# DDR32SS0_CTLPHY_WRAP_CTL_CFG_CTLCFG register map
Vendor: Texas Instruments
Registers are 32-bit, read-write, reset 0x0 unless marked. A register's access mark holds for its fields unless they carry their own. Offsets are as the file gives them; [hi:lo] are bit positions; lines under a group give offsets from that group; {n}, {i} and the like mark numbered series.

## DDR32SS0_CTLPHY_WRAP_CTL_CFG_CTLCFG (part 5 of 11)
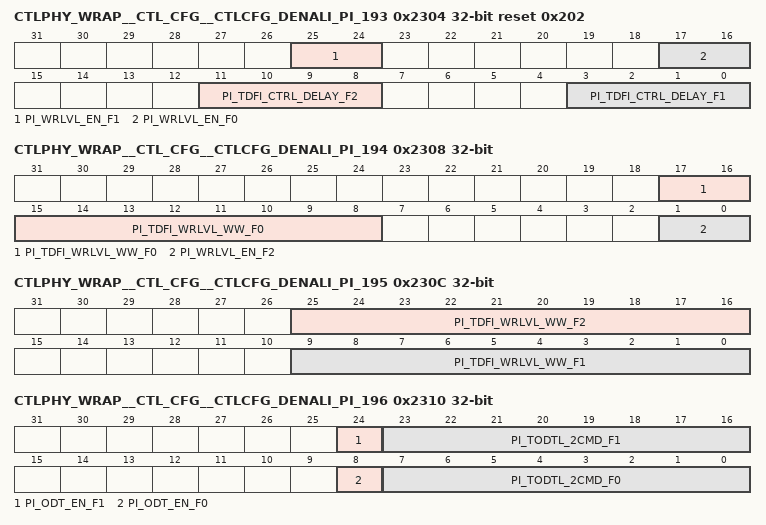
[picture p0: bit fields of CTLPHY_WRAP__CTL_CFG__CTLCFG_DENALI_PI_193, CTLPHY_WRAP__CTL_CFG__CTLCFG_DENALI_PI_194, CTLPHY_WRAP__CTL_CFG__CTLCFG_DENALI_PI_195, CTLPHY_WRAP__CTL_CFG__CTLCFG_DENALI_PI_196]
0x2304 CTLPHY_WRAP__CTL_CFG__CTLCFG_DENALI_PI_193 reset 0x202
  [25:24] PI_WRLVL_EN_F1 — Enable the PI write leveling module for frequency set 1. Bit[1] represents the support when non-initialization. Bit[0]represents the support when initialization. Set to 1 to enable.
  [17:16] PI_WRLVL_EN_F0 — Enable the PI write leveling module for frequency set 0. Bit[1] represents the support when non-initialization. Bit[0]represents the support when initialization. Set to 1 to enable.
  [11:8] PI_TDFI_CTRL_DELAY_F2 — Defines the DFI tCTRL_DELAY timing parameter [in DFI clocks] for frequency set 2, the delay between a DFI command change and a memory command.
  [3:0] PI_TDFI_CTRL_DELAY_F1 — Defines the DFI tCTRL_DELAY timing parameter [in DFI clocks] for frequency set 1, the delay between a DFI command change and a memory command.
0x2308 CTLPHY_WRAP__CTL_CFG__CTLCFG_DENALI_PI_194
  [17:8] PI_TDFI_WRLVL_WW_F0 — Defines the DFI tWRLVL_WW timing parameter [in DFI clocks] for frequency set 0, the minimum cycles between dfi_wrlvl_strobe assertions.
  [1:0] PI_WRLVL_EN_F2 — Enable the PI write leveling module for frequency set 2. Bit[1] represents the support when non-initialization. Bit[0]represents the support when initialization. Set to 1 to enable.
0x230C CTLPHY_WRAP__CTL_CFG__CTLCFG_DENALI_PI_195
  [25:16] PI_TDFI_WRLVL_WW_F2 — Defines the DFI tWRLVL_WW timing parameter [in DFI clocks] for frequency set 2, the minimum cycles between dfi_wrlvl_strobe assertions.
  [9:0] PI_TDFI_WRLVL_WW_F1 — Defines the DFI tWRLVL_WW timing parameter [in DFI clocks] for frequency set 1, the minimum cycles between dfi_wrlvl_strobe assertions.
0x2310 CTLPHY_WRAP__CTL_CFG__CTLCFG_DENALI_PI_196
  [24] PI_ODT_EN_F1 — Enable support of DRAM ODT. When enabled, PI will assert and de-assert ODT output to DRAM as needed for frequency set 1.
  [23:16] PI_TODTL_2CMD_F1 — Defines the DRAM delay from an ODT de-assertion to the next non-write, non-read command for frequency set 1.
  [8] PI_ODT_EN_F0 — Enable support of DRAM ODT. When enabled, PI will assert and de-assert ODT output to DRAM as needed for frequency set 0.
  [7:0] PI_TODTL_2CMD_F0 — Defines the DRAM delay from an ODT de-assertion to the next non-write, non-read command for frequency set 0.
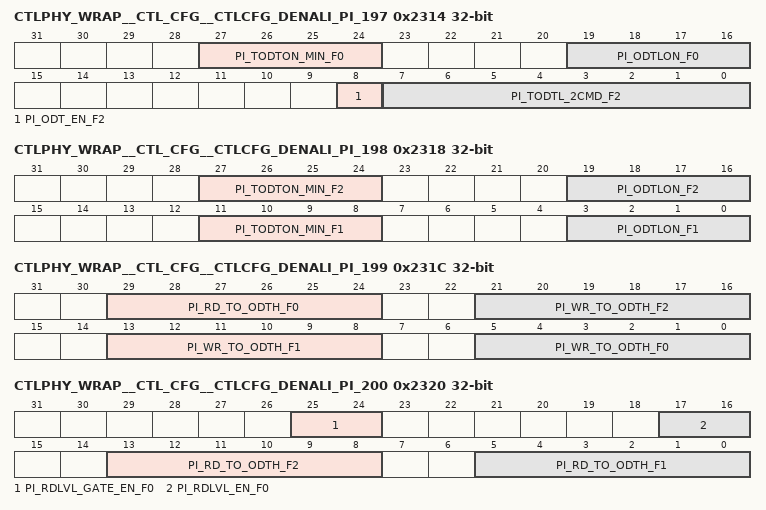
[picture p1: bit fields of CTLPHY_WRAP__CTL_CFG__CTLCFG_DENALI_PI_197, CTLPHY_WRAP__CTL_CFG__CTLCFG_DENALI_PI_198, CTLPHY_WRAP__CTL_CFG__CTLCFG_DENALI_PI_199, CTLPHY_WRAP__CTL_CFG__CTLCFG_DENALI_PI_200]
0x2314 CTLPHY_WRAP__CTL_CFG__CTLCFG_DENALI_PI_197
  [27:24] PI_TODTON_MIN_F0 — Defines the point in time when the device termination circuit leaves High-Z and ODT resistance begins to turn on for frequency set 0.
  [19:16] PI_ODTLON_F0 — Defines the latency from a CAS-2 command to the tODTon reference for frequency set 0.
  [8] PI_ODT_EN_F2 — Enable support of DRAM ODT. When enabled, PI will assert and de-assert ODT output to DRAM as needed for frequency set 2.
  [7:0] PI_TODTL_2CMD_F2 — Defines the DRAM delay from an ODT de-assertion to the next non-write, non-read command for frequency set 2.
0x2318 CTLPHY_WRAP__CTL_CFG__CTLCFG_DENALI_PI_198
  [27:24] PI_TODTON_MIN_F2 — Defines the point in time when the device termination circuit leaves High-Z and ODT resistance begins to turn on for frequency set 2.
  [19:16] PI_ODTLON_F2 — Defines the latency from a CAS-2 command to the tODTon reference for frequency set 2.
  [11:8] PI_TODTON_MIN_F1 — Defines the point in time when the device termination circuit leaves High-Z and ODT resistance begins to turn on for frequency set 1.
  [3:0] PI_ODTLON_F1 — Defines the latency from a CAS-2 command to the tODTon reference for frequency set 1.
0x231C CTLPHY_WRAP__CTL_CFG__CTLCFG_DENALI_PI_199
  [29:24] PI_RD_TO_ODTH_F0 — Defines the delay from a read command to ODT assertion for frequency set 0.
  [21:16] PI_WR_TO_ODTH_F2 — Defines the delay from a write command to ODT assertion for frequency set 2.
  [13:8] PI_WR_TO_ODTH_F1 — Defines the delay from a write command to ODT assertion for frequency set 1.
  [5:0] PI_WR_TO_ODTH_F0 — Defines the delay from a write command to ODT assertion for frequency set 0.
0x2320 CTLPHY_WRAP__CTL_CFG__CTLCFG_DENALI_PI_200
  [25:24] PI_RDLVL_GATE_EN_F0 — Enable the PI gate training module for frequency set 0. Bit[1] represents the support when non-initialization. Bit[0]represents the support when initialization. Set to 1 to enable.
  [17:16] PI_RDLVL_EN_F0 — Enable the PI data eye training module for frequency set 0. Bit[1] represents the support when non-initialization. Bit[0]represents the support when initialization. Set to 1 to enable.
  [13:8] PI_RD_TO_ODTH_F2 — Defines the delay from a read command to ODT assertion for frequency set 2.
  [5:0] PI_RD_TO_ODTH_F1 — Defines the delay from a read command to ODT assertion for frequency set 1.
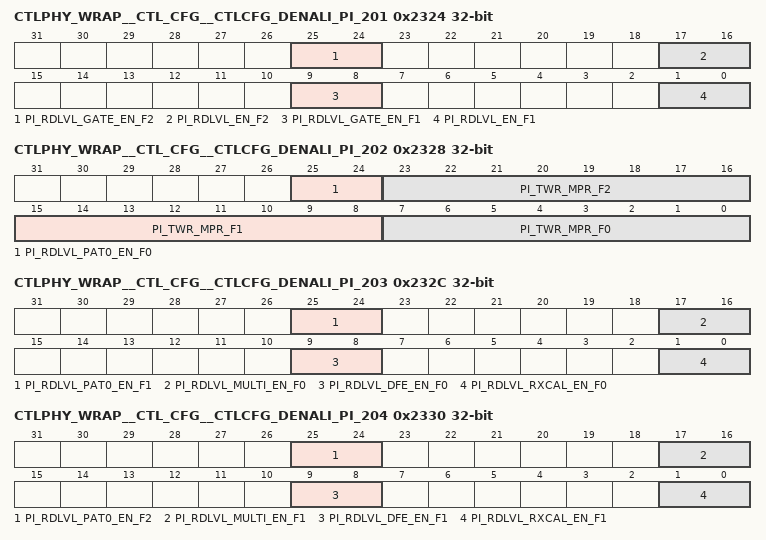
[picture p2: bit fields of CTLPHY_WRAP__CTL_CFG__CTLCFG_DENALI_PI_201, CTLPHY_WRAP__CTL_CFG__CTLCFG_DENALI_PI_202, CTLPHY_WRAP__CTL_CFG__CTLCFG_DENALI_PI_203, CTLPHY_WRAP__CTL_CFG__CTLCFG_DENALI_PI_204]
0x2324 CTLPHY_WRAP__CTL_CFG__CTLCFG_DENALI_PI_201
  [25:24] PI_RDLVL_GATE_EN_F2 — Enable the PI gate training module for frequency set 2. Bit[1] represents the support when non-initialization. Bit[0]represents the support when initialization. Set to 1 to enable.
  [17:16] PI_RDLVL_EN_F2 — Enable the PI data eye training module for frequency set 2. Bit[1] represents the support when non-initialization. Bit[0]represents the support when initialization. Set to 1 to enable.
  [9:8] PI_RDLVL_GATE_EN_F1 — Enable the PI gate training module for frequency set 1. Bit[1] represents the support when non-initialization. Bit[0]represents the support when initialization. Set to 1 to enable.
  [1:0] PI_RDLVL_EN_F1 — Enable the PI data eye training module for frequency set 1. Bit[1] represents the support when non-initialization. Bit[0]represents the support when initialization. Set to 1 to enable.
0x2328 CTLPHY_WRAP__CTL_CFG__CTLCFG_DENALI_PI_202
  [25:24] PI_RDLVL_PAT0_EN_F0 — Enable PATTERN-0 for read training for frequency set 0. bit1 for normal; bit0 for initialization.
  [23:16] PI_TWR_MPR_F2 — Number of cycles after MPR write command and before any other command for frequency set 2.
  [15:8] PI_TWR_MPR_F1 — Number of cycles after MPR write command and before any other command for frequency set 1.
  [7:0] PI_TWR_MPR_F0 — Number of cycles after MPR write command and before any other command for frequency set 0.
0x232C CTLPHY_WRAP__CTL_CFG__CTLCFG_DENALI_PI_203
  [25:24] PI_RDLVL_PAT0_EN_F1 — Enable PATTERN-0 for read training for frequency set 1. bit1 for normal; bit0 for initialization.
  [17:16] PI_RDLVL_MULTI_EN_F0 — Enable Multi-pattern [from PI_RDLVL_PATTERN_START, total PI_RDLVL_PATTERN_NUM] for read training for frequency set 0. bit1 for normal; bit0 for initialization.
  [9:8] PI_RDLVL_DFE_EN_F0 — Enable DFE [PATTERN 8,9] for read training for frequency set 0. bit1 for normal; bit0 for initialization.
  [1:0] PI_RDLVL_RXCAL_EN_F0 — Enable RX Offset calibration [PATTERN 14,15] for read training for frequency set 0. bit1 for normal; bit0 for initialization.
0x2330 CTLPHY_WRAP__CTL_CFG__CTLCFG_DENALI_PI_204
  [25:24] PI_RDLVL_PAT0_EN_F2 — Enable PATTERN-0 for read training for frequency set 2. bit1 for normal; bit0 for initialization.
  [17:16] PI_RDLVL_MULTI_EN_F1 — Enable Multi-pattern [from PI_RDLVL_PATTERN_START, total PI_RDLVL_PATTERN_NUM] for read training for frequency set 1. bit1 for normal; bit0 for initialization.
  [9:8] PI_RDLVL_DFE_EN_F1 — Enable DFE [PATTERN 8,9] for read training for frequency set 1. bit1 for normal; bit0 for initialization.
  [1:0] PI_RDLVL_RXCAL_EN_F1 — Enable RX Offset calibration [PATTERN 14,15] for read training for frequency set 1. bit1 for normal; bit0 for initialization.
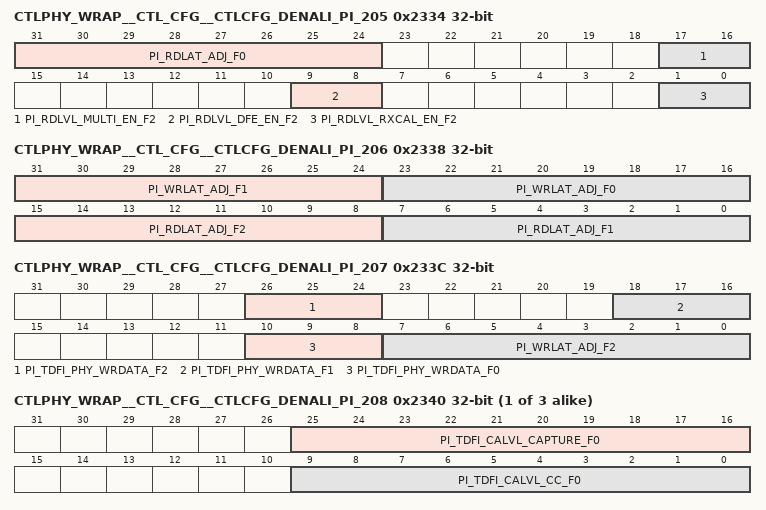
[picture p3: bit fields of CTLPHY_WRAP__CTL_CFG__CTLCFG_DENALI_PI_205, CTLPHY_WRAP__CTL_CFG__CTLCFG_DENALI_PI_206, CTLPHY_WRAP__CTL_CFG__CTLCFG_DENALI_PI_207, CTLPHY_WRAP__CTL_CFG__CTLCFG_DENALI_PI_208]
0x2334 CTLPHY_WRAP__CTL_CFG__CTLCFG_DENALI_PI_205
  [31:24] PI_RDLAT_ADJ_F0 — Adjusts the relative timing between DFI read commands and the dfi_rddata_en signal for frequency set 0.
  [17:16] PI_RDLVL_MULTI_EN_F2 — Enable Multi-pattern [from PI_RDLVL_PATTERN_START, total PI_RDLVL_PATTERN_NUM] for read training for frequency set 2. bit1 for normal; bit0 for initialization.
  [9:8] PI_RDLVL_DFE_EN_F2 — Enable DFE [PATTERN 8,9] for read training for frequency set 2. bit1 for normal; bit0 for initialization.
  [1:0] PI_RDLVL_RXCAL_EN_F2 — Enable RX Offset calibration [PATTERN 14,15] for read training for frequency set 2. bit1 for normal; bit0 for initialization.
0x2338 CTLPHY_WRAP__CTL_CFG__CTLCFG_DENALI_PI_206
  [31:24] PI_WRLAT_ADJ_F1 — Adjusts the relative timing in memory clocks between DFI write commands and the dfi_wrdata_en signal for frequency set 1.
  [23:16] PI_WRLAT_ADJ_F0 — Adjusts the relative timing in memory clocks between DFI write commands and the dfi_wrdata_en signal for frequency set 0.
  [15:8] PI_RDLAT_ADJ_F2 — Adjusts the relative timing between DFI read commands and the dfi_rddata_en signal for frequency set 2.
  [7:0] PI_RDLAT_ADJ_F1 — Adjusts the relative timing between DFI read commands and the dfi_rddata_en signal for frequency set 1.
0x233C CTLPHY_WRAP__CTL_CFG__CTLCFG_DENALI_PI_207
  [26:24] PI_TDFI_PHY_WRDATA_F2 — Defines the DFI tPHY_WRDATA timing parameter [in DFI PHY clocks] for frequency set 2, the maximum cycles between a dfi_wrdata_en assertion and a dfi_wrdata signal.
  [18:16] PI_TDFI_PHY_WRDATA_F1 — Defines the DFI tPHY_WRDATA timing parameter [in DFI PHY clocks] for frequency set 1, the maximum cycles between a dfi_wrdata_en assertion and a dfi_wrdata signal.
  [10:8] PI_TDFI_PHY_WRDATA_F0 — Defines the DFI tPHY_WRDATA timing parameter [in DFI PHY clocks] for frequency set 0, the maximum cycles between a dfi_wrdata_en assertion and a dfi_wrdata signal.
  [7:0] PI_WRLAT_ADJ_F2 — Adjusts the relative timing in memory clocks between DFI write commands and the dfi_wrdata_en signal for frequency set 2.
{0x2000+4i} CTLPHY_WRAP__CTL_CFG__CTLCFG_DENALI_PI_{i} (i=208..210)
  [25:16] PI_TDFI_CALVL_CAPTURE_F{i-208} — Defines the DFI tCALVL_CAPTURE timing parameter [in DFI clocks] for frequency set {i-208}, the minimum cycles between a calibration command and a dfi_calvl_capture pulse.
  [9:0] PI_TDFI_CALVL_CC_F{i-208} — Defines the DFI tCALVL_CC timing parameter [in DFI clocks] for frequency set {i-208}, the minimum cycles between calibration commands.
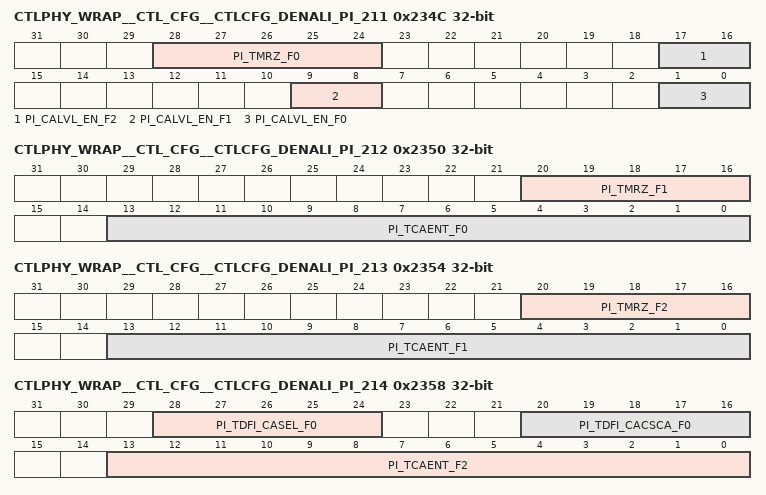
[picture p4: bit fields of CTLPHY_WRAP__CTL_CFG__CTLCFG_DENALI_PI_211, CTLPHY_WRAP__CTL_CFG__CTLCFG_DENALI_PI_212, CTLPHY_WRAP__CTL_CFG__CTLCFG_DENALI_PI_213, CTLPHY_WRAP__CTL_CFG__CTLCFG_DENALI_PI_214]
0x234C CTLPHY_WRAP__CTL_CFG__CTLCFG_DENALI_PI_211
  [28:24] PI_TMRZ_F0 — Defines the delay between a MRW CA exit command and the DQ tristate in memory clocks for frequency set 0.
  [17:16] PI_CALVL_EN_F2 — Enable the PI CA training module. Bit[1] represents the support when non-initialization for frequency set 2. Bit[0]represents the support when initialization. Set to 1 to enable.
  [9:8] PI_CALVL_EN_F1 — Enable the PI CA training module. Bit[1] represents the support when non-initialization for frequency set 1. Bit[0]represents the support when initialization. Set to 1 to enable.
  [1:0] PI_CALVL_EN_F0 — Enable the PI CA training module. Bit[1] represents the support when non-initialization for frequency set 0. Bit[0]represents the support when initialization. Set to 1 to enable.
0x2350 CTLPHY_WRAP__CTL_CFG__CTLCFG_DENALI_PI_212
  [20:16] PI_TMRZ_F1 — Defines the delay between a MRW CA exit command and the DQ tristate in memory clocks for frequency set 1.
  [13:0] PI_TCAENT_F0 — Defines the DRAM tCAENT term, in memory clocks for frequency set 0.
0x2354 CTLPHY_WRAP__CTL_CFG__CTLCFG_DENALI_PI_213
  [20:16] PI_TMRZ_F2 — Defines the delay between a MRW CA exit command and the DQ tristate in memory clocks for frequency set 2.
  [13:0] PI_TCAENT_F1 — Defines the DRAM tCAENT term, in memory clocks for frequency set 1.
0x2358 CTLPHY_WRAP__CTL_CFG__CTLCFG_DENALI_PI_214
  [28:24] PI_TDFI_CASEL_F0 — Defines the DFI tcalvl_ca_sel timing parameter, the width of dfi_calvl_ca_sel in PHY DFI clock cycles for frequency set 0.
  [20:16] PI_TDFI_CACSCA_F0 — Defines the DFI tcalvl_cs_ca timing parameter, the number of PHY DFI clocks from the assertion of dfi_calvl_ca_sel to the assertion of dfi_cs for frequency set 0.
  [13:0] PI_TCAENT_F2 — Defines the DRAM tCAENT term, in memory clocks for frequency set 2.
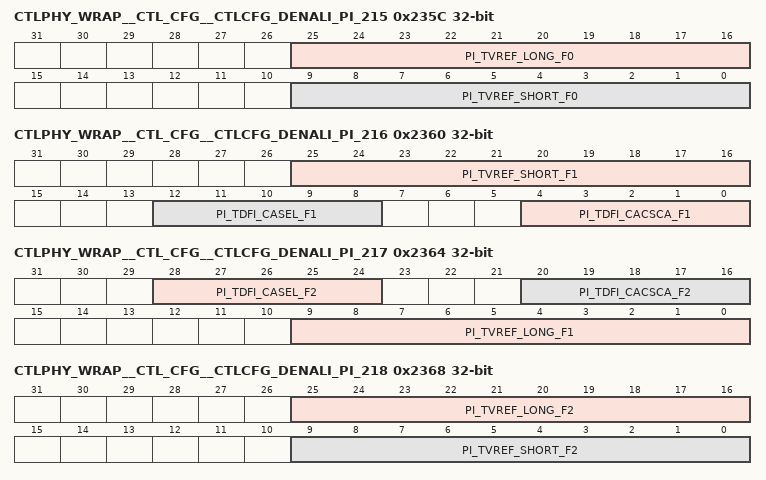
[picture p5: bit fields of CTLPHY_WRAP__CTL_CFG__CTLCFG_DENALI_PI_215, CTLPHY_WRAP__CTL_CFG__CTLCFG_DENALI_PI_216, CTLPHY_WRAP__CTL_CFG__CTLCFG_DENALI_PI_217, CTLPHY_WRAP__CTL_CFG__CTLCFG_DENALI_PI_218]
0x235C CTLPHY_WRAP__CTL_CFG__CTLCFG_DENALI_PI_215
  [25:16] PI_TVREF_LONG_F0 — Defines the delay in PI clock cycles between the dfi_calvl_strobe to the next command if the pi_calvl_vref_stepsize parameter gt 1 for frequency set 0.
  [9:0] PI_TVREF_SHORT_F0 — Defines the delay in PI clock cycles between the dfi_calvl_strobe to the next command if the pi_calvl_vref_stepsize parameter = 1 for frequency set 0.
0x2360 CTLPHY_WRAP__CTL_CFG__CTLCFG_DENALI_PI_216
  [25:16] PI_TVREF_SHORT_F1 — Defines the delay in PI clock cycles between the dfi_calvl_strobe to the next command if the pi_calvl_vref_stepsize parameter = 1 for frequency set 1.
  [12:8] PI_TDFI_CASEL_F1 — Defines the DFI tcalvl_ca_sel timing parameter, the width of dfi_calvl_ca_sel in PHY DFI clock cycles for frequency set 1.
  [4:0] PI_TDFI_CACSCA_F1 — Defines the DFI tcalvl_cs_ca timing parameter, the number of PHY DFI clocks from the assertion of dfi_calvl_ca_sel to the assertion of dfi_cs for frequency set 1.
0x2364 CTLPHY_WRAP__CTL_CFG__CTLCFG_DENALI_PI_217
  [28:24] PI_TDFI_CASEL_F2 — Defines the DFI tcalvl_ca_sel timing parameter, the width of dfi_calvl_ca_sel in PHY DFI clock cycles for frequency set 2.
  [20:16] PI_TDFI_CACSCA_F2 — Defines the DFI tcalvl_cs_ca timing parameter, the number of PHY DFI clocks from the assertion of dfi_calvl_ca_sel to the assertion of dfi_cs for frequency set 2.
  [9:0] PI_TVREF_LONG_F1 — Defines the delay in PI clock cycles between the dfi_calvl_strobe to the next command if the pi_calvl_vref_stepsize parameter gt 1 for frequency set 1.
0x2368 CTLPHY_WRAP__CTL_CFG__CTLCFG_DENALI_PI_218
  [25:16] PI_TVREF_LONG_F2 — Defines the delay in PI clock cycles between the dfi_calvl_strobe to the next command if the pi_calvl_vref_stepsize parameter gt 1 for frequency set 2.
  [9:0] PI_TVREF_SHORT_F2 — Defines the delay in PI clock cycles between the dfi_calvl_strobe to the next command if the pi_calvl_vref_stepsize parameter = 1 for frequency set 2.
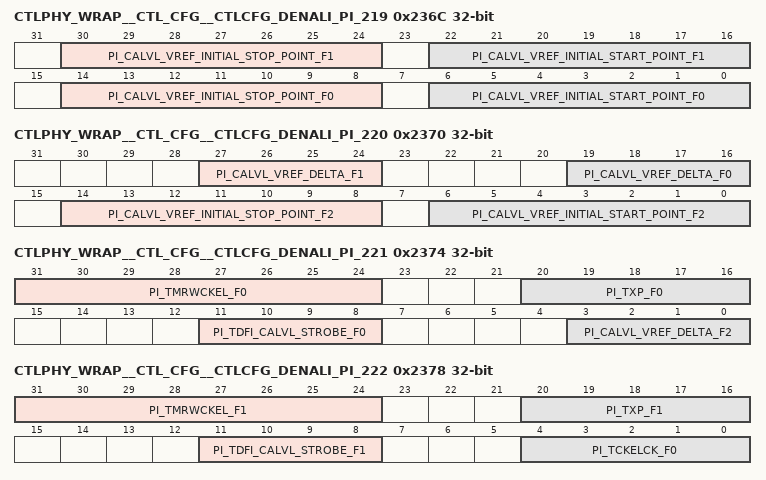
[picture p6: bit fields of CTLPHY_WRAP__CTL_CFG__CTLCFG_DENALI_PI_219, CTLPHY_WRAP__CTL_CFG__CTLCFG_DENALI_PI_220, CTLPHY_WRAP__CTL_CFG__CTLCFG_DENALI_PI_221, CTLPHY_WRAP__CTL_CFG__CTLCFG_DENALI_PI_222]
0x236C CTLPHY_WRAP__CTL_CFG__CTLCFG_DENALI_PI_219
  [30:24] PI_CALVL_VREF_INITIAL_STOP_POINT_F1 — The end point of initial training for the Vref[ca] training for frequency set 1 { vrefca_range, vref_ca_setting[5:0]}.
  [22:16] PI_CALVL_VREF_INITIAL_START_POINT_F1 — The start point of initial training for the Vref[ca] training for frequency set 1 { vrefca_range, vref_ca_setting[5:0]}.
  [14:8] PI_CALVL_VREF_INITIAL_STOP_POINT_F0 — The end point of initial training for the Vref[ca] training for frequency set 0 { vrefca_range, vref_ca_setting[5:0]}.
  [6:0] PI_CALVL_VREF_INITIAL_START_POINT_F0 — The start point of initial training for the Vref[ca] training for frequency set 0 { vrefca_range, vref_ca_setting[5:0]}.
0x2370 CTLPHY_WRAP__CTL_CFG__CTLCFG_DENALI_PI_220
  [27:24] PI_CALVL_VREF_DELTA_F1 — The delta fro the current CA vref for non-initial CA training for frequency set 1.
  [19:16] PI_CALVL_VREF_DELTA_F0 — The delta fro the current CA vref for non-initial CA training for frequency set 0.
  [14:8] PI_CALVL_VREF_INITIAL_STOP_POINT_F2 — The end point of initial training for the Vref[ca] training for frequency set 2 { vrefca_range, vref_ca_setting[5:0]}.
  [6:0] PI_CALVL_VREF_INITIAL_START_POINT_F2 — The start point of initial training for the Vref[ca] training for frequency set 2 { vrefca_range, vref_ca_setting[5:0]}.
0x2374 CTLPHY_WRAP__CTL_CFG__CTLCFG_DENALI_PI_221
  [31:24] PI_TMRWCKEL_F0 — Valid Clock and CS Requirement before CKE deassert after MRW Command for frequency set 0.
  [20:16] PI_TXP_F0 — CKE assert to next valid command delay for frequency set 0.
  [11:8] PI_TDFI_CALVL_STROBE_F0 — Minimum number of DFI PHY clocks from dfi_calvl_data to dfi_calvl_strobe mode for frequency set 0.
  [3:0] PI_CALVL_VREF_DELTA_F2 — The delta fro the current CA vref for non-initial CA training for frequency set 2.
0x2378 CTLPHY_WRAP__CTL_CFG__CTLCFG_DENALI_PI_222
  [31:24] PI_TMRWCKEL_F1 — Valid Clock and CS Requirement before CKE deassert after MRW Command for frequency set 1.
  [20:16] PI_TXP_F1 — CKE assert to next valid command delay for frequency set 1.
  [11:8] PI_TDFI_CALVL_STROBE_F1 — Minimum number of DFI PHY clocks from dfi_calvl_data to dfi_calvl_strobe mode for frequency set 1.
  [4:0] PI_TCKELCK_F0 — Valid Clock Requirement after CKE deassert for frequency set 0.
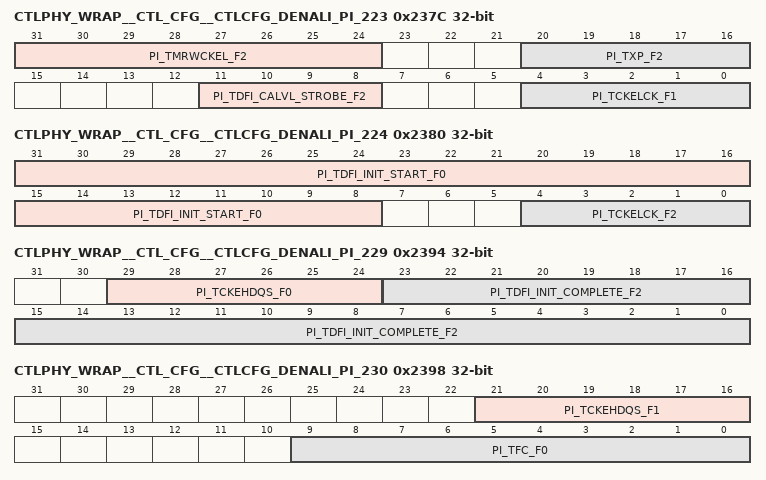
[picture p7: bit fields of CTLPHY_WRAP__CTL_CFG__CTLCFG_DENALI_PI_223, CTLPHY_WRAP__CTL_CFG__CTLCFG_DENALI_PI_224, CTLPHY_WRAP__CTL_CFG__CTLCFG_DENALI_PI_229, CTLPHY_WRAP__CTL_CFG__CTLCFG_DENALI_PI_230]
0x237C CTLPHY_WRAP__CTL_CFG__CTLCFG_DENALI_PI_223
  [31:24] PI_TMRWCKEL_F2 — Valid Clock and CS Requirement before CKE deassert after MRW Command for frequency set 2.
  [20:16] PI_TXP_F2 — CKE assert to next valid command delay for frequency set 2.
  [11:8] PI_TDFI_CALVL_STROBE_F2 — Minimum number of DFI PHY clocks from dfi_calvl_data to dfi_calvl_strobe mode for frequency set 2.
  [4:0] PI_TCKELCK_F1 — Valid Clock Requirement after CKE deassert for frequency set 1.
0x2380 CTLPHY_WRAP__CTL_CFG__CTLCFG_DENALI_PI_224
  [31:8] PI_TDFI_INIT_START_F0 — Defines the DFI tINIT_START timing parameter [in DFI clocks] for frequency set 0, the maximum number of cycles between a dfi_init_start assertion and a dfi_init_complete de-assertion from the PHY.
  [4:0] PI_TCKELCK_F2 — Valid Clock Requirement after CKE deassert for frequency set 2.
0x2384 CTLPHY_WRAP__CTL_CFG__CTLCFG_DENALI_PI_225
  [23:0] PI_TDFI_INIT_COMPLETE_F0 — Defines the DFI tINIT_COMPLETE timing parameter [in DFI clocks] for frequency set 0, the maximum cycles between a dfi_init_start de-assertion and a dfi_init_complete assertion from the PHY.
0x2388 CTLPHY_WRAP__CTL_CFG__CTLCFG_DENALI_PI_226
  [23:0] PI_TDFI_INIT_START_F1 — Defines the DFI tINIT_START timing parameter [in DFI clocks] for frequency set 1, the maximum number of cycles between a dfi_init_start assertion and a dfi_init_complete de-assertion from the PHY.
0x238C CTLPHY_WRAP__CTL_CFG__CTLCFG_DENALI_PI_227
  [23:0] PI_TDFI_INIT_COMPLETE_F1 — Defines the DFI tINIT_COMPLETE timing parameter [in DFI clocks] for frequency set 1, the maximum cycles between a dfi_init_start de-assertion and a dfi_init_complete assertion from the PHY.
0x2390 CTLPHY_WRAP__CTL_CFG__CTLCFG_DENALI_PI_228
  [23:0] PI_TDFI_INIT_START_F2 — Defines the DFI tINIT_START timing parameter [in DFI clocks] for frequency set 2, the maximum number of cycles between a dfi_init_start assertion and a dfi_init_complete de-assertion from the PHY.
0x2394 CTLPHY_WRAP__CTL_CFG__CTLCFG_DENALI_PI_229
  [29:24] PI_TCKEHDQS_F0 — The DRAM timing tCKEHDQS, minimum delay from CKE high to strobe high impedance for frequency set 0.
  [23:0] PI_TDFI_INIT_COMPLETE_F2 — Defines the DFI tINIT_COMPLETE timing parameter [in DFI clocks] for frequency set 2, the maximum cycles between a dfi_init_start de-assertion and a dfi_init_complete assertion from the PHY.
0x2398 CTLPHY_WRAP__CTL_CFG__CTLCFG_DENALI_PI_230
  [21:16] PI_TCKEHDQS_F1 — The DRAM timing tCKEHDQS, minimum delay from CKE high to strobe high impedance for frequency set 1.
  [9:0] PI_TFC_F0 — The delay in PHY clock cycles from setting MR13.OP7 to any valid command for frequency set 0.
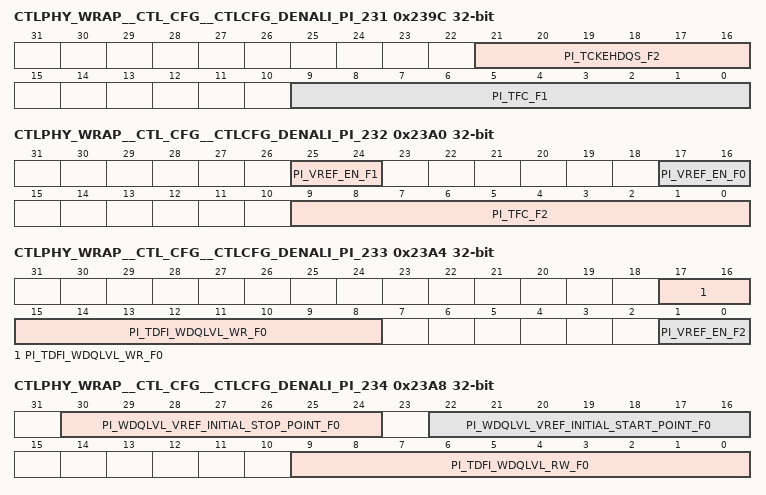
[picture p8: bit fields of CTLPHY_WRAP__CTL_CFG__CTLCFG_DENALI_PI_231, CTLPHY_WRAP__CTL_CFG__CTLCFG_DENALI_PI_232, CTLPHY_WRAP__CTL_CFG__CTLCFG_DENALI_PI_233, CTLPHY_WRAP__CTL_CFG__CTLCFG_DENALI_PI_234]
0x239C CTLPHY_WRAP__CTL_CFG__CTLCFG_DENALI_PI_231
  [21:16] PI_TCKEHDQS_F2 — The DRAM timing tCKEHDQS, minimum delay from CKE high to strobe high impedance for frequency set 2.
  [9:0] PI_TFC_F1 — The delay in PHY clock cycles from setting MR13.OP7 to any valid command for frequency set 1.
0x23A0 CTLPHY_WRAP__CTL_CFG__CTLCFG_DENALI_PI_232
  [25:24] PI_VREF_EN_F1 — Enable VREF training during power-up initialization for frequency set 1. Bit[1] represents the support when non-initialization. Bit[0]represents the support when initialization. Set to 1 to enable.
  [17:16] PI_VREF_EN_F0 — Enable VREF training during power-up initialization for frequency set 0. Bit[1] represents the support when non-initialization. Bit[0]represents the support when initialization. Set to 1 to enable.
  [9:0] PI_TFC_F2 — The delay in PHY clock cycles from setting MR13.OP7 to any valid command for frequency set 2.
0x23A4 CTLPHY_WRAP__CTL_CFG__CTLCFG_DENALI_PI_233
  [17:8] PI_TDFI_WDQLVL_WR_F0 — Switch time from write to read for frequency set 0.
  [1:0] PI_VREF_EN_F2 — Enable VREF training during power-up initialization for frequency set 2. Bit[1] represents the support when non-initialization. Bit[0]represents the support when initialization. Set to 1 to enable.
0x23A8 CTLPHY_WRAP__CTL_CFG__CTLCFG_DENALI_PI_234
  [30:24] PI_WDQLVL_VREF_INITIAL_STOP_POINT_F0 — Write DQ training vref initial training stop value for frequency set 0.
  [22:16] PI_WDQLVL_VREF_INITIAL_START_POINT_F0 — Write DQ training vref initial training start value for frequency set 0.
  [9:0] PI_TDFI_WDQLVL_RW_F0 — Switch time from read to write for frequency set 0.
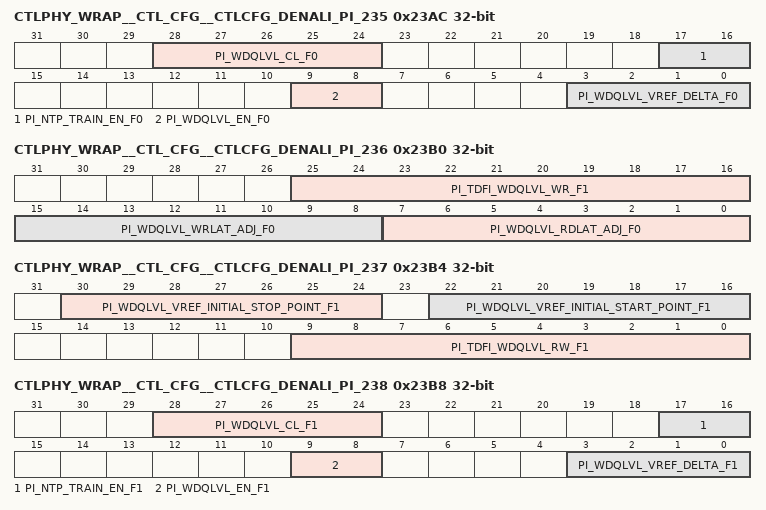
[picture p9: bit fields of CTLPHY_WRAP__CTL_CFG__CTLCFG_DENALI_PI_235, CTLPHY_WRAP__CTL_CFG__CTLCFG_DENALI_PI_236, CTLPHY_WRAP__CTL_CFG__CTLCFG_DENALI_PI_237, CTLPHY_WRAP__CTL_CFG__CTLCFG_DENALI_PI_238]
0x23AC CTLPHY_WRAP__CTL_CFG__CTLCFG_DENALI_PI_235
  [28:24] PI_WDQLVL_CL_F0 — CL when the Read DBI disabled while doing WDQ training for frequency set 0.
  [17:16] PI_NTP_TRAIN_EN_F0 — Indicates whether the no topology WDQ training is enabled. Bit[1] represents the support when non-initialization. Bit[0]represents the support when initialization.
  [9:8] PI_WDQLVL_EN_F0 — Indicates if Write DQ leveling is enabled for frequency set 0. Bit[1] represents the support when non-initialization. Bit[0]represents the support when initialization.
  [3:0] PI_WDQLVL_VREF_DELTA_F0 — The delta from the current Write DQ vref adjustment for non-initial wdq training for frequency set 0.
0x23B0 CTLPHY_WRAP__CTL_CFG__CTLCFG_DENALI_PI_236
  [25:16] PI_TDFI_WDQLVL_WR_F1 — Switch time from write to read for frequency set 1.
  [15:8] PI_WDQLVL_WRLAT_ADJ_F0 — Adjusted Tdfi_wrdata_en value for PHY read timing when read dbi disabled for frequency set 0, used for WDQ training.
  [7:0] PI_WDQLVL_RDLAT_ADJ_F0 — Adjusted Tdfi_rddata_en value for PHY read timing when read dbi disabled for frequency set 0, used for WDQ training.
0x23B4 CTLPHY_WRAP__CTL_CFG__CTLCFG_DENALI_PI_237
  [30:24] PI_WDQLVL_VREF_INITIAL_STOP_POINT_F1 — Write DQ training vref initial training stop value for frequency set 1.
  [22:16] PI_WDQLVL_VREF_INITIAL_START_POINT_F1 — Write DQ training vref initial training start value for frequency set 1.
  [9:0] PI_TDFI_WDQLVL_RW_F1 — Switch time from read to write for frequency set 1.
0x23B8 CTLPHY_WRAP__CTL_CFG__CTLCFG_DENALI_PI_238
  [28:24] PI_WDQLVL_CL_F1 — CL when the Read DBI disabled while doing WDQ training for frequency set 1.
  [17:16] PI_NTP_TRAIN_EN_F1 — Indicates whether the no topology WDQ training is enabled. Bit[1] represents the support when non-initialization. Bit[0]represents the support when initialization.
  [9:8] PI_WDQLVL_EN_F1 — Indicates if Write DQ leveling is enabled for frequency set 1. Bit[1] represents the support when non-initialization. Bit[0]represents the support when initialization.
  [3:0] PI_WDQLVL_VREF_DELTA_F1 — The delta from the current Write DQ vref adjustment for non-initial wdq training for frequency set 1.
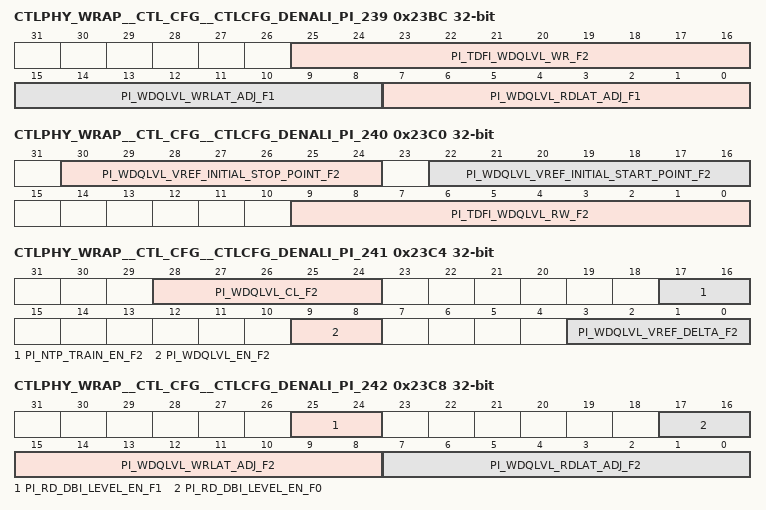
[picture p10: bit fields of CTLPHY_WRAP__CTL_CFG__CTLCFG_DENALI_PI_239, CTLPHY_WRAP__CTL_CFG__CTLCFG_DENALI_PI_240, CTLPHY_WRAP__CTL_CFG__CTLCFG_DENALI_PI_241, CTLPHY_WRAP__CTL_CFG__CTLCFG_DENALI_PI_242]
0x23BC CTLPHY_WRAP__CTL_CFG__CTLCFG_DENALI_PI_239
  [25:16] PI_TDFI_WDQLVL_WR_F2 — Switch time from write to read for frequency set 2.
  [15:8] PI_WDQLVL_WRLAT_ADJ_F1 — Adjusted Tdfi_wrdata_en value for PHY read timing when read dbi disabled for frequency set 1, used for WDQ training.
  [7:0] PI_WDQLVL_RDLAT_ADJ_F1 — Adjusted Tdfi_rddata_en value for PHY read timing when read dbi disabled for frequency set 1, used for WDQ training.
0x23C0 CTLPHY_WRAP__CTL_CFG__CTLCFG_DENALI_PI_240
  [30:24] PI_WDQLVL_VREF_INITIAL_STOP_POINT_F2 — Write DQ training vref initial training stop value for frequency set 2.
  [22:16] PI_WDQLVL_VREF_INITIAL_START_POINT_F2 — Write DQ training vref initial training start value for frequency set 2.
  [9:0] PI_TDFI_WDQLVL_RW_F2 — Switch time from read to write for frequency set 2.
0x23C4 CTLPHY_WRAP__CTL_CFG__CTLCFG_DENALI_PI_241
  [28:24] PI_WDQLVL_CL_F2 — CL when the Read DBI disabled while doing WDQ training for frequency set 2.
  [17:16] PI_NTP_TRAIN_EN_F2 — Indicates whether the no topology WDQ training is enabled. Bit[1] represents the support when non-initialization. Bit[0]represents the support when initialization.
  [9:8] PI_WDQLVL_EN_F2 — Indicates if Write DQ leveling is enabled for frequency set 2. Bit[1] represents the support when non-initialization. Bit[0]represents the support when initialization.
  [3:0] PI_WDQLVL_VREF_DELTA_F2 — The delta from the current Write DQ vref adjustment for non-initial wdq training for frequency set 2.
0x23C8 CTLPHY_WRAP__CTL_CFG__CTLCFG_DENALI_PI_242
  [25:24] PI_RD_DBI_LEVEL_EN_F1 — Read DBI leveling enable, only can be enabled when READ DBI supported for DDR4, and PI_WDQLVL_EN or PI_RDLVL_EN configured by 1 for frequency set 1. Bit[1] represents the support when non-initialization. Bit[0]represents the support when initialization.
  [17:16] PI_RD_DBI_LEVEL_EN_F0 — Read DBI leveling enable, only can be enabled when READ DBI supported for DDR4, and PI_WDQLVL_EN or PI_RDLVL_EN configured by 1 for frequency set 0. Bit[1] represents the support when non-initialization. Bit[0]represents the support when initialization.
  [15:8] PI_WDQLVL_WRLAT_ADJ_F2 — Adjusted Tdfi_wrdata_en value for PHY read timing when read dbi disabled for frequency set 2, used for WDQ training.
  [7:0] PI_WDQLVL_RDLAT_ADJ_F2 — Adjusted Tdfi_rddata_en value for PHY read timing when read dbi disabled for frequency set 2, used for WDQ training.
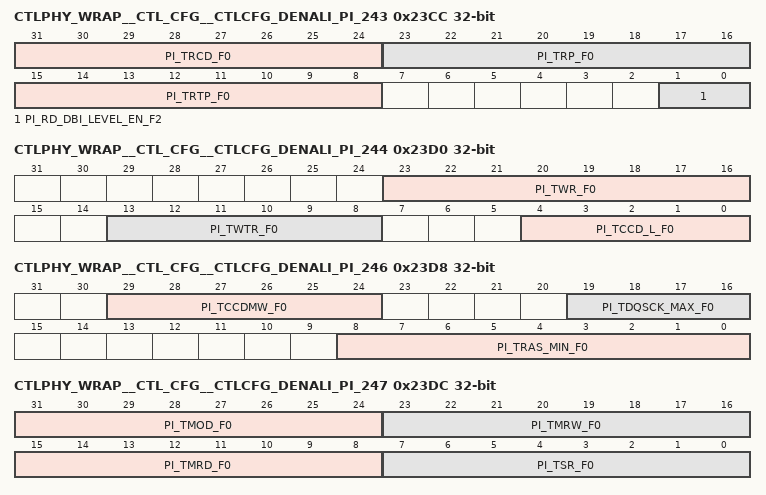
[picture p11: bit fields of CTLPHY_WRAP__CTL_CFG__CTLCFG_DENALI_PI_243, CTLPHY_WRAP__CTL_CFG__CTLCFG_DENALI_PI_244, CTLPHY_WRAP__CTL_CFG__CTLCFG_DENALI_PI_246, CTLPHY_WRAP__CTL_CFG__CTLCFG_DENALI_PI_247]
0x23CC CTLPHY_WRAP__CTL_CFG__CTLCFG_DENALI_PI_243
  [31:24] PI_TRCD_F0 — DRAM tRCD value in cycles for frequency set 0.
  [23:16] PI_TRP_F0 — DRAM tRP value in cycles for frequency set 0.
  [15:8] PI_TRTP_F0 — DRAM tRTP value in cycles for frequency set 0.
  [1:0] PI_RD_DBI_LEVEL_EN_F2 — Read DBI leveling enable, only can be enabled when READ DBI supported for DDR4, and PI_WDQLVL_EN or PI_RDLVL_EN configured by 1 for frequency set 2. Bit[1] represents the support when non-initialization. Bit[0]represents the support when initialization.
0x23D0 CTLPHY_WRAP__CTL_CFG__CTLCFG_DENALI_PI_244
  [23:16] PI_TWR_F0 — DRAM tWR value in cycles for frequency set 0.
  [13:8] PI_TWTR_F0 — DRAM tWTR value in cycles for frequency set 0.
  [4:0] PI_TCCD_L_F0 — DRAM CAS-to_CAS value within the same bank group in cycles for frequency set 0.
0x23D4 CTLPHY_WRAP__CTL_CFG__CTLCFG_DENALI_PI_245
  [19:0] PI_TRAS_MAX_F0 — DRAM tRAS_MAX value in cycles for frequency set 0.
0x23D8 CTLPHY_WRAP__CTL_CFG__CTLCFG_DENALI_PI_246
  [29:24] PI_TCCDMW_F0 — LPDDR4 DRAM tCCDMW in cycles for frequency set 0.
  [19:16] PI_TDQSCK_MAX_F0 — Additional delay needed for tDQSCK for frequency set 0.
  [8:0] PI_TRAS_MIN_F0 — DRAM tRAS_MIN value in cycles for frequency set 0.
0x23DC CTLPHY_WRAP__CTL_CFG__CTLCFG_DENALI_PI_247
  [31:24] PI_TMOD_F0 — DRAM tMOD value in cycles for frequency set 0.
  [23:16] PI_TMRW_F0 — DRAM tMRW value in cycles for frequency set 0.
  [15:8] PI_TMRD_F0 — DRAM tMRD value in cycles for frequency set 0.
  [7:0] PI_TSR_F0 — Min cycles from sref entry to sref exit for frequency set 0.
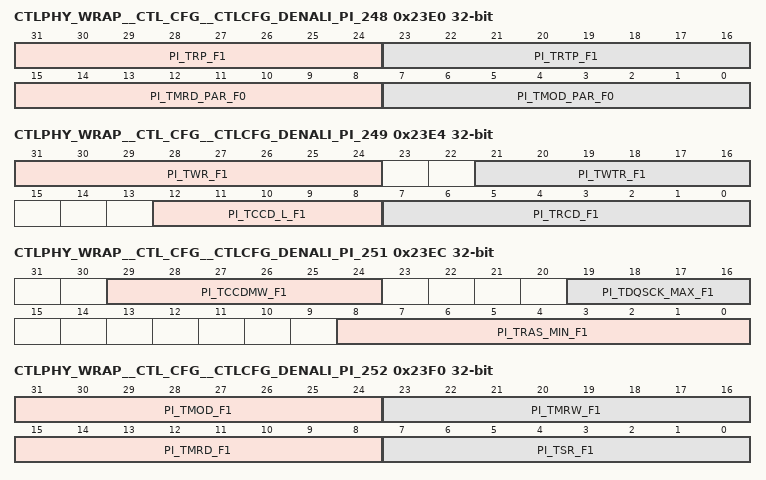
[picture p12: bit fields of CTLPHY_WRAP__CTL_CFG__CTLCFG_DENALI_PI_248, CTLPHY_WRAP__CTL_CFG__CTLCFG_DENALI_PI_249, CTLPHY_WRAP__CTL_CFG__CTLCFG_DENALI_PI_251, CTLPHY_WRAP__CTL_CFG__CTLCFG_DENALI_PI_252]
0x23E0 CTLPHY_WRAP__CTL_CFG__CTLCFG_DENALI_PI_248
  [31:24] PI_TRP_F1 — DRAM tRP value in cycles for frequency set 1.
  [23:16] PI_TRTP_F1 — DRAM tRTP value in cycles for frequency set 1.
  [15:8] PI_TMRD_PAR_F0 — DRAM tMRD value when CA parity is enabled in cycles for frequency set 0.
  [7:0] PI_TMOD_PAR_F0 — DRAM tMOD value when CA parity is enabled in cycles for frequency set 0.
0x23E4 CTLPHY_WRAP__CTL_CFG__CTLCFG_DENALI_PI_249
  [31:24] PI_TWR_F1 — DRAM tWR value in cycles for frequency set 1.
  [21:16] PI_TWTR_F1 — DRAM tWTR value in cycles for frequency set 1.
  [12:8] PI_TCCD_L_F1 — DRAM CAS-to_CAS value within the same bank group in cycles for frequency set 1.
  [7:0] PI_TRCD_F1 — DRAM tRCD value in cycles for frequency set 1.
0x23E8 CTLPHY_WRAP__CTL_CFG__CTLCFG_DENALI_PI_250
  [19:0] PI_TRAS_MAX_F1 — DRAM tRAS_MAX value in cycles for frequency set 1.
0x23EC CTLPHY_WRAP__CTL_CFG__CTLCFG_DENALI_PI_251
  [29:24] PI_TCCDMW_F1 — LPDDR4 DRAM tCCDMW in cycles for frequency set 1.
  [19:16] PI_TDQSCK_MAX_F1 — Additional delay needed for tDQSCK for frequency set 1.
  [8:0] PI_TRAS_MIN_F1 — DRAM tRAS_MIN value in cycles for frequency set 1.
0x23F0 CTLPHY_WRAP__CTL_CFG__CTLCFG_DENALI_PI_252
  [31:24] PI_TMOD_F1 — DRAM tMOD value in cycles for frequency set 1.
  [23:16] PI_TMRW_F1 — DRAM tMRW value in cycles for frequency set 1.
  [15:8] PI_TMRD_F1 — DRAM tMRD value in cycles for frequency set 1.
  [7:0] PI_TSR_F1 — Min cycles from sref entry to sref exit for frequency set 1.
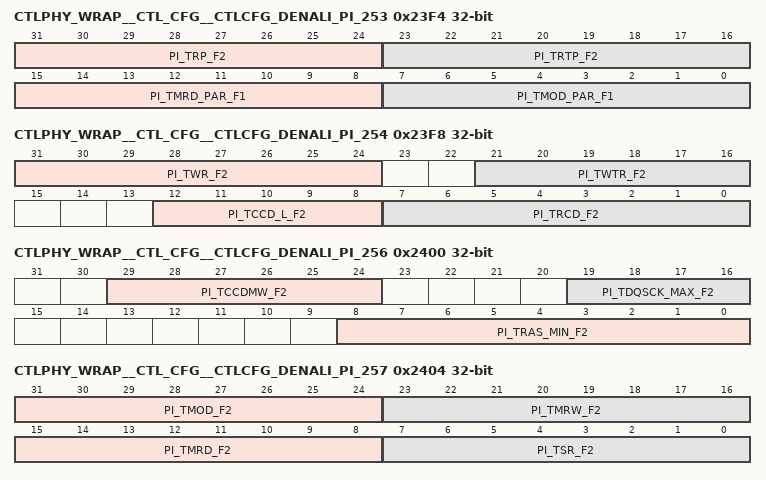
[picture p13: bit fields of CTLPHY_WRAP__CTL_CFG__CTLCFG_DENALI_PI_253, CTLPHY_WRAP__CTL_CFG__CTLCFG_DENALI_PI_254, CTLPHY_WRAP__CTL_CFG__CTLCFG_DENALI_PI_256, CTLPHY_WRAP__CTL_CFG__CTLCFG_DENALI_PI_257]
0x23F4 CTLPHY_WRAP__CTL_CFG__CTLCFG_DENALI_PI_253
  [31:24] PI_TRP_F2 — DRAM tRP value in cycles for frequency set 2.
  [23:16] PI_TRTP_F2 — DRAM tRTP value in cycles for frequency set 2.
  [15:8] PI_TMRD_PAR_F1 — DRAM tMRD value when CA parity is enabled in cycles for frequency set 1.
  [7:0] PI_TMOD_PAR_F1 — DRAM tMOD value when CA parity is enabled in cycles for frequency set 1.
0x23F8 CTLPHY_WRAP__CTL_CFG__CTLCFG_DENALI_PI_254
  [31:24] PI_TWR_F2 — DRAM tWR value in cycles for frequency set 2.
  [21:16] PI_TWTR_F2 — DRAM tWTR value in cycles for frequency set 2.
  [12:8] PI_TCCD_L_F2 — DRAM CAS-to_CAS value within the same bank group in cycles for frequency set 2.
  [7:0] PI_TRCD_F2 — DRAM tRCD value in cycles for frequency set 2.
0x23FC CTLPHY_WRAP__CTL_CFG__CTLCFG_DENALI_PI_255
  [19:0] PI_TRAS_MAX_F2 — DRAM tRAS_MAX value in cycles for frequency set 2.
0x2400 CTLPHY_WRAP__CTL_CFG__CTLCFG_DENALI_PI_256
  [29:24] PI_TCCDMW_F2 — LPDDR4 DRAM tCCDMW in cycles for frequency set 2.
  [19:16] PI_TDQSCK_MAX_F2 — Additional delay needed for tDQSCK for frequency set 2.
  [8:0] PI_TRAS_MIN_F2 — DRAM tRAS_MIN value in cycles for frequency set 2.
0x2404 CTLPHY_WRAP__CTL_CFG__CTLCFG_DENALI_PI_257
  [31:24] PI_TMOD_F2 — DRAM tMOD value in cycles for frequency set 2.
  [23:16] PI_TMRW_F2 — DRAM tMRW value in cycles for frequency set 2.
  [15:8] PI_TMRD_F2 — DRAM tMRD value in cycles for frequency set 2.
  [7:0] PI_TSR_F2 — Min cycles from sref entry to sref exit for frequency set 2.
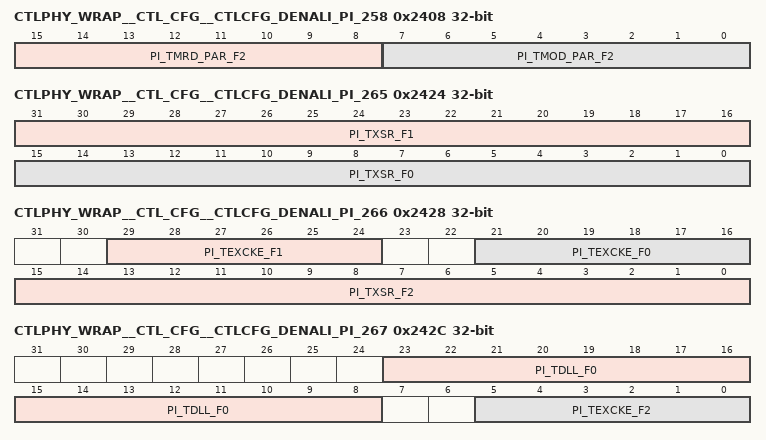
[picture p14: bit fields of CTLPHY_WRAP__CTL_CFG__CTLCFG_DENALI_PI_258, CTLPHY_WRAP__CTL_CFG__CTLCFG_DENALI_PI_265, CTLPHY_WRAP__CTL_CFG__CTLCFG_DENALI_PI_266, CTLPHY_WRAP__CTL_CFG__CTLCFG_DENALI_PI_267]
0x2408 CTLPHY_WRAP__CTL_CFG__CTLCFG_DENALI_PI_258
  [15:8] PI_TMRD_PAR_F2 — DRAM tMRD value when CA parity is enabled in cycles for frequency set 2.
  [7:0] PI_TMOD_PAR_F2 — DRAM tMOD value when CA parity is enabled in cycles for frequency set 2.
0x240C CTLPHY_WRAP__CTL_CFG__CTLCFG_DENALI_PI_259
  [20:0] PI_TDFI_CTRLUPD_MAX_F0 — Defines the DFI tCTRLUPD_MAX timing parameter [in DFI clocks] for frequency set 0, the maximum cycles that dfi_ctrlupd_req can be asserted. If programmed to a non-zero, a timing violation will cause an interrupt and bit [1] set in the PI_UPDATE_ERROR_STATUS parameter.
0x2410 CTLPHY_WRAP__CTL_CFG__CTLCFG_DENALI_PI_260
  [31:0] PI_TDFI_CTRLUPD_INTERVAL_F0 — Defines the DFI tCTRLUPD_INTERVAL timing parameter [in DFI clocks] for frequency set 0, the maximum cycles between dfi_ctrlupd_req assertions. If programmed to a non-zero, a timing violation will cause an interrupt and bit [0] set in the PI_UPDATE_ERROR_STATUS parameter.
0x2414 CTLPHY_WRAP__CTL_CFG__CTLCFG_DENALI_PI_261
  [20:0] PI_TDFI_CTRLUPD_MAX_F1 — Defines the DFI tCTRLUPD_MAX timing parameter [in DFI clocks] for frequency set 1, the maximum cycles that dfi_ctrlupd_req can be asserted. If programmed to a non-zero, a timing violation will cause an interrupt and bit [1] set in the PI_UPDATE_ERROR_STATUS parameter.
0x2418 CTLPHY_WRAP__CTL_CFG__CTLCFG_DENALI_PI_262
  [31:0] PI_TDFI_CTRLUPD_INTERVAL_F1 — Defines the DFI tCTRLUPD_INTERVAL timing parameter [in DFI clocks] for frequency set 1, the maximum cycles between dfi_ctrlupd_req assertions. If programmed to a non-zero, a timing violation will cause an interrupt and bit [0] set in the PI_UPDATE_ERROR_STATUS parameter.
0x241C CTLPHY_WRAP__CTL_CFG__CTLCFG_DENALI_PI_263
  [20:0] PI_TDFI_CTRLUPD_MAX_F2 — Defines the DFI tCTRLUPD_MAX timing parameter [in DFI clocks] for frequency set 2, the maximum cycles that dfi_ctrlupd_req can be asserted. If programmed to a non-zero, a timing violation will cause an interrupt and bit [1] set in the PI_UPDATE_ERROR_STATUS parameter.
0x2420 CTLPHY_WRAP__CTL_CFG__CTLCFG_DENALI_PI_264
  [31:0] PI_TDFI_CTRLUPD_INTERVAL_F2 — Defines the DFI tCTRLUPD_INTERVAL timing parameter [in DFI clocks] for frequency set 2, the maximum cycles between dfi_ctrlupd_req assertions. If programmed to a non-zero, a timing violation will cause an interrupt and bit [0] set in the PI_UPDATE_ERROR_STATUS parameter.
0x2424 CTLPHY_WRAP__CTL_CFG__CTLCFG_DENALI_PI_265
  [31:16] PI_TXSR_F1 — DRAM TXSR value for frequency set 1 in cycles.
  [15:0] PI_TXSR_F0 — DRAM TXSR value for frequency set 0 in cycles.
0x2428 CTLPHY_WRAP__CTL_CFG__CTLCFG_DENALI_PI_266
  [29:24] PI_TEXCKE_F1 — DRAM CKE low after SREF command timing for frequency set 1.
  [21:16] PI_TEXCKE_F0 — DRAM CKE low after SREF command timing for frequency set 0.
  [15:0] PI_TXSR_F2 — DRAM TXSR value for frequency set 2 in cycles.
0x242C CTLPHY_WRAP__CTL_CFG__CTLCFG_DENALI_PI_267
  [23:8] PI_TDLL_F0 — DRAM tDLL value for frequency set 0 in cycles.
  [5:0] PI_TEXCKE_F2 — DRAM CKE low after SREF command timing for frequency set 2.
0x2430 CTLPHY_WRAP__CTL_CFG__CTLCFG_DENALI_PI_268
  [31:16] PI_TDLL_F2 — DRAM tDLL value for frequency set 2 in cycles.
  [15:0] PI_TDLL_F1 — DRAM tDLL value for frequency set 1 in cycles.
0x2434 CTLPHY_WRAP__CTL_CFG__CTLCFG_DENALI_PI_269
  [31:24] PI_TCKSRE_F1 — DRAM tCKSRE value.
  [23:16] PI_TCKSRX_F1 — DRAM tCKSRX value.
  [15:8] PI_TCKSRE_F0 — DRAM tCKSRE value.
  [7:0] PI_TCKSRX_F0 — DRAM tCKSRX value.
0x2438 CTLPHY_WRAP__CTL_CFG__CTLCFG_DENALI_PI_270
  [15:8] PI_TCKSRE_F2 — DRAM tCKSRE value.
  [7:0] PI_TCKSRX_F2 — DRAM tCKSRX value.
0x243C CTLPHY_WRAP__CTL_CFG__CTLCFG_DENALI_PI_271
  [23:0] PI_TINIT_F0 — DRAM tINIT value for frequency set 0 in cycles.
{0x2000+4i} CTLPHY_WRAP__CTL_CFG__CTLCFG_DENALI_PI_{i} (i=272..274)
  [23:0] PI_TINIT{i-269}_F0 — DRAM tINIT{i-269} value for frequency set 0 in cycles.
0x244C CTLPHY_WRAP__CTL_CFG__CTLCFG_DENALI_PI_275
  [15:0] PI_TXSNR_F0 — DRAM tXSNR value for frequency set 0 in cycles.
0x2450 CTLPHY_WRAP__CTL_CFG__CTLCFG_DENALI_PI_276
  [23:0] PI_TINIT_F1 — DRAM tINIT value for frequency set 1 in cycles.
{0x2000+4i} CTLPHY_WRAP__CTL_CFG__CTLCFG_DENALI_PI_{i} (i=277..279)
  [23:0] PI_TINIT{i-274}_F1 — DRAM tINIT{i-274} value for frequency set 1 in cycles.
0x2460 CTLPHY_WRAP__CTL_CFG__CTLCFG_DENALI_PI_280
  [15:0] PI_TXSNR_F1 — DRAM tXSNR value for frequency set 1 in cycles.
0x2464 CTLPHY_WRAP__CTL_CFG__CTLCFG_DENALI_PI_281
  [23:0] PI_TINIT_F2 — DRAM tINIT value for frequency set 2 in cycles.
{0x2000+4i} CTLPHY_WRAP__CTL_CFG__CTLCFG_DENALI_PI_{i} (i=282..284)
  [23:0] PI_TINIT{i-279}_F2 — DRAM tINIT{i-279} value for frequency set 2 in cycles.
0x2474 CTLPHY_WRAP__CTL_CFG__CTLCFG_DENALI_PI_285
  [15:0] PI_TXSNR_F2 — DRAM tXSNR value for frequency set 2 in cycles.
0x2478 CTLPHY_WRAP__CTL_CFG__CTLCFG_DENALI_PI_286
  [27:16] PI_TZQCAL_F0 — Holds the DRAM ZQCAL value for frequency set 0 in cycles.
0x247C CTLPHY_WRAP__CTL_CFG__CTLCFG_DENALI_PI_287
  [6:0] PI_TZQLAT_F0 — Holds the DRAM ZQLAT value for frequency set 0 in cycles.
0x2480 CTLPHY_WRAP__CTL_CFG__CTLCFG_DENALI_PI_288
  [27:16] PI_TZQCAL_F1 — Holds the DRAM ZQCAL value for frequency set 1 in cycles.
0x2484 CTLPHY_WRAP__CTL_CFG__CTLCFG_DENALI_PI_289
  [6:0] PI_TZQLAT_F1 — Holds the DRAM ZQLAT value for frequency set 1 in cycles.
0x2488 CTLPHY_WRAP__CTL_CFG__CTLCFG_DENALI_PI_290
  [27:16] PI_TZQCAL_F2 — Holds the DRAM ZQCAL value for frequency set 2 in cycles.
0x248C CTLPHY_WRAP__CTL_CFG__CTLCFG_DENALI_PI_291
  [6:0] PI_TZQLAT_F2 — Holds the DRAM ZQLAT value for frequency set 2 in cycles.
0x2490 CTLPHY_WRAP__CTL_CFG__CTLCFG_DENALI_PI_292 access not given reset not defined
0x2494 CTLPHY_WRAP__CTL_CFG__CTLCFG_DENALI_PI_293
  [25:24] PI_PREAMBLE_SUPPORT_F0 — bit0: Selection of one or two cycle preamble for read burst transfers. bit1: Selection of one or two cycles write burst transfers for NON-DDR5,one or multi[up to four] cycles write burst transfers for DDR5.
  [19:16] PI_WDQ_OSC_DELTA_INDEX_F2 — WDQ DQS delay delta index for OSC triggered periodic training for frequency set 2. If the value is n, the delay is 2^n/512 cycle.
  [11:8] PI_WDQ_OSC_DELTA_INDEX_F1 — WDQ DQS delay delta index for OSC triggered periodic training for frequency set 1. If the value is n, the delay is 2^n/512 cycle.
  [3:0] PI_WDQ_OSC_DELTA_INDEX_F0 — WDQ DQS delay delta index for OSC triggered periodic training for frequency set 0. If the value is n, the delay is 2^n/512 cycle.
0x2498 CTLPHY_WRAP__CTL_CFG__CTLCFG_DENALI_PI_294
  [26:24] PI_MEMDATA_RATIO_1 — Defines the ratio of the DRAM device size on chip select 1 to the memory data width. Program with the log2 ratio of the memory data width to the device data width.
  [18:16] PI_MEMDATA_RATIO_0 — Defines the ratio of the DRAM device size on chip select 0 to the memory data width. Program with the log2 ratio of the memory data width to the device data width.
  [9:8] PI_PREAMBLE_SUPPORT_F2 — bit0: Selection of one or two cycle preamble for read burst transfers. bit1: Selection of one or two cycles write burst transfers for NON-DDR5,one or multi[up to four] cycles write burst transfers for DDR5.
  [1:0] PI_PREAMBLE_SUPPORT_F1 — bit0: Selection of one or two cycle preamble for read burst transfers. bit1: Selection of one or two cycles write burst transfers for NON-DDR5,one or multi[up to four] cycles write burst transfers for DDR5.
0x249C CTLPHY_WRAP__CTL_CFG__CTLCFG_DENALI_PI_295
  [27:24] PI_ODT_WR_MAP_CS0 — Determines which chip[s] will have termination when a write occurs on chip select 0. Set bit X to enable termination on csX when cs0 is performing a write.
  [19:16] PI_ODT_RD_MAP_CS0 — Determines which chip[s] will have termination when a read occurs on chip select 0. Set bit X to enable termination on csX when cs0 is performing a read.
  [10:8] PI_MEMDATA_RATIO_3 — Defines the ratio of the DRAM device size on chip select 3 to the memory data width. Program with the log2 ratio of the memory data width to the device data width.
  [2:0] PI_MEMDATA_RATIO_2 — Defines the ratio of the DRAM device size on chip select 2 to the memory data width. Program with the log2 ratio of the memory data width to the device data width.
0x24A0 CTLPHY_WRAP__CTL_CFG__CTLCFG_DENALI_PI_296
  [27:24] PI_ODT_WR_MAP_CS2 — Determines which chip[s] will have termination when a write occurs on chip select 2. Set bit X to enable termination on csX when cs2 is performing a write.
  [19:16] PI_ODT_RD_MAP_CS2 — Determines which chip[s] will have termination when a read occurs on chip select 2. Set bit X to enable termination on csX when cs2 is performing a read.
  [11:8] PI_ODT_WR_MAP_CS1 — Determines which chip[s] will have termination when a write occurs on chip select 1. Set bit X to enable termination on csX when cs1 is performing a write.
  [3:0] PI_ODT_RD_MAP_CS1 — Determines which chip[s] will have termination when a read occurs on chip select 1. Set bit X to enable termination on csX when cs1 is performing a read.
0x24A4 CTLPHY_WRAP__CTL_CFG__CTLCFG_DENALI_PI_297
  [30:24] PI_VREF_VAL_DEV0_1 — Defines the range and value for VREF training for DRAM 0 for CS 1. If the PI_VREF_PDA_EN parameter is not set, device 0 values are used for all devices.
  [22:16] PI_VREF_VAL_DEV0_0 — Defines the range and value for VREF training for DRAM 0 for CS 0. If the PI_VREF_PDA_EN parameter is not set, device 0 values are used for all devices.
  [11:8] PI_ODT_WR_MAP_CS3 — Determines which chip[s] will have termination when a write occurs on chip select 3. Set bit X to enable termination on csX when cs3 is performing a write.
  [3:0] PI_ODT_RD_MAP_CS3 — Determines which chip[s] will have termination when a read occurs on chip select 3. Set bit X to enable termination on csX when cs3 is performing a read.
{0x2000+4i} CTLPHY_WRAP__CTL_CFG__CTLCFG_DENALI_PI_{i} (i=298..300)
  [30:24] PI_VREF_VAL_DEV{i-297}_1 — Defines the range and value for VREF training for DRAM {i-297} for CS 1. If the PI_VREF_PDA_EN parameter is not set, device 0 values are used for all devices.
  [22:16] PI_VREF_VAL_DEV{i-297}_0 — Defines the range and value for VREF training for DRAM {i-297} for CS 0. If the PI_VREF_PDA_EN parameter is not set, device 0 values are used for all devices.
  [14:8] PI_VREF_VAL_DEV{i-298}_3 — Defines the range and value for VREF training for DRAM {i-298} for CS 3. If the PI_VREF_PDA_EN parameter is not set, device 0 values are used for all devices.
  [6:0] PI_VREF_VAL_DEV{i-298}_2 — Defines the range and value for VREF training for DRAM {i-298} for CS 2. If the PI_VREF_PDA_EN parameter is not set, device 0 values are used for all devices.
0x24B4 CTLPHY_WRAP__CTL_CFG__CTLCFG_DENALI_PI_301
  [25:24] PI_SLICE_PER_DEV_1 — Indicates the number of data slices per memory device. The device width divided by 8.
  [17:16] PI_SLICE_PER_DEV_0 — Indicates the number of data slices per memory device. The device width divided by 8.
  [14:8] PI_VREF_VAL_DEV3_3 — Defines the range and value for VREF training for DRAM 3 for CS 3. If the PI_VREF_PDA_EN parameter is not set, device 0 values are used for all devices.
  [6:0] PI_VREF_VAL_DEV3_2 — Defines the range and value for VREF training for DRAM 3 for CS 2. If the PI_VREF_PDA_EN parameter is not set, device 0 values are used for all devices.
0x24B8 CTLPHY_WRAP__CTL_CFG__CTLCFG_DENALI_PI_302 access per field
  [29:24] PI_MR6_VREF_0_1 ro — The parameter stores the vref value of every devices of the same CS. It is updated after WDQLVL PDA mode completed. READ-ONLY.
  [21:16] PI_MR6_VREF_0_0 ro — The parameter stores the vref value of every devices of the same CS. It is updated after WDQLVL PDA mode completed. READ-ONLY.
  [9:8] PI_SLICE_PER_DEV_3 rw — Indicates the number of data slices per memory device. The device width divided by 8.
  [1:0] PI_SLICE_PER_DEV_2 rw — Indicates the number of data slices per memory device. The device width divided by 8.
{0x2000+4i} CTLPHY_WRAP__CTL_CFG__CTLCFG_DENALI_PI_{i} ro (i=303..305)
  [29:24] PI_MR6_VREF_{i-302}_1 — The parameter stores the vref value of every devices of the same CS. It is updated after WDQLVL PDA mode completed. READ-ONLY.
  [21:16] PI_MR6_VREF_{i-302}_0 — The parameter stores the vref value of every devices of the same CS. It is updated after WDQLVL PDA mode completed. READ-ONLY.
  [13:8] PI_MR6_VREF_{i-303}_3 — The parameter stores the vref value of every devices of the same CS. It is updated after WDQLVL PDA mode completed. READ-ONLY.
  [5:0] PI_MR6_VREF_{i-303}_2 — The parameter stores the vref value of every devices of the same CS. It is updated after WDQLVL PDA mode completed. READ-ONLY.
0x24C8 CTLPHY_WRAP__CTL_CFG__CTLCFG_DENALI_PI_306 access per field
  [31:24] PI_MR15_DATA_0 rw — Data to program into memory mode register 15 for chip select 0.
  [23:16] PI_MR13_DATA_0 rw — Data to program into memory mode register 13 for chip select 0.
  [13:8] PI_MR6_VREF_3_3 ro — The parameter stores the vref value of every devices of the same CS. It is updated after WDQLVL PDA mode completed. READ-ONLY.
  [5:0] PI_MR6_VREF_3_2 ro — The parameter stores the vref value of every devices of the same CS. It is updated after WDQLVL PDA mode completed. READ-ONLY.
0x24CC CTLPHY_WRAP__CTL_CFG__CTLCFG_DENALI_PI_307
  [23:16] PI_MR20_DATA_0 — Data to program into memory mode register 20 for chip select 0.
  [15:8] PI_MR17_DATA_0 — Data to program into memory mode register 17 for chip select 0.
  [7:0] PI_MR16_DATA_0 — Data to program into memory mode register 16 for chip select 0.
0x24D0 CTLPHY_WRAP__CTL_CFG__CTLCFG_DENALI_PI_308
  [31:24] PI_MR40_DATA_0 — Data to program into memory mode register 40 for chip select 0.
  [16:0] PI_MR32_DATA_0 — Data to program into memory mode register 32 for chip select 0.
0x24D4 CTLPHY_WRAP__CTL_CFG__CTLCFG_DENALI_PI_309
  [31:24] PI_MR17_DATA_1 — Data to program into memory mode register 17 for chip select 1.
  [23:16] PI_MR16_DATA_1 — Data to program into memory mode register 16 for chip select 1.
  [15:8] PI_MR15_DATA_1 — Data to program into memory mode register 15 for chip select 1.
  [7:0] PI_MR13_DATA_1 — Data to program into memory mode register 13 for chip select 1.
0x24D8 CTLPHY_WRAP__CTL_CFG__CTLCFG_DENALI_PI_310
  [24:8] PI_MR32_DATA_1 — Data to program into memory mode register 32 for chip select 1.
  [7:0] PI_MR20_DATA_1 — Data to program into memory mode register 20 for chip select 1.
0x24DC CTLPHY_WRAP__CTL_CFG__CTLCFG_DENALI_PI_311
  [31:24] PI_MR16_DATA_2 — Data to program into memory mode register 16 for chip select 2.
  [23:16] PI_MR15_DATA_2 — Data to program into memory mode register 15 for chip select 2.
  [15:8] PI_MR13_DATA_2 — Data to program into memory mode register 13 for chip select 2.
  [7:0] PI_MR40_DATA_1 — Data to program into memory mode register 40 for chip select 1.
